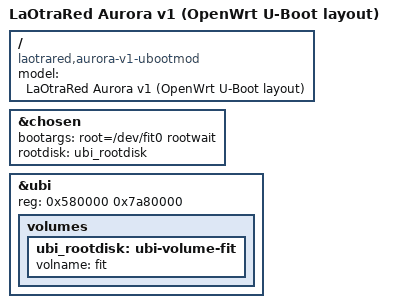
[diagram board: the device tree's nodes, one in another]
// SPDX-License-Identifier: GPL-2.0-only OR MIT

/dts-v1/;

#include "mt7981b-laotrared-aurora-v1.dtsi"

/ {
	model = "LaOtraRed Aurora v1 (OpenWrt U-Boot layout)";
	compatible = "laotrared,aurora-v1-ubootmod", "mediatek,mt7981";
};

&chosen {
	bootargs = "root=/dev/fit0 rootwait";
	rootdisk = <&ubi_rootdisk>;
};

&ubi {
	reg = <0x580000 0x7a80000>;

	volumes {
		ubi_rootdisk: ubi-volume-fit {
			volname = "fit";
		};
	};
};
